AUTOSAR XML (schema 4-3-0)
package /ComponentTypes
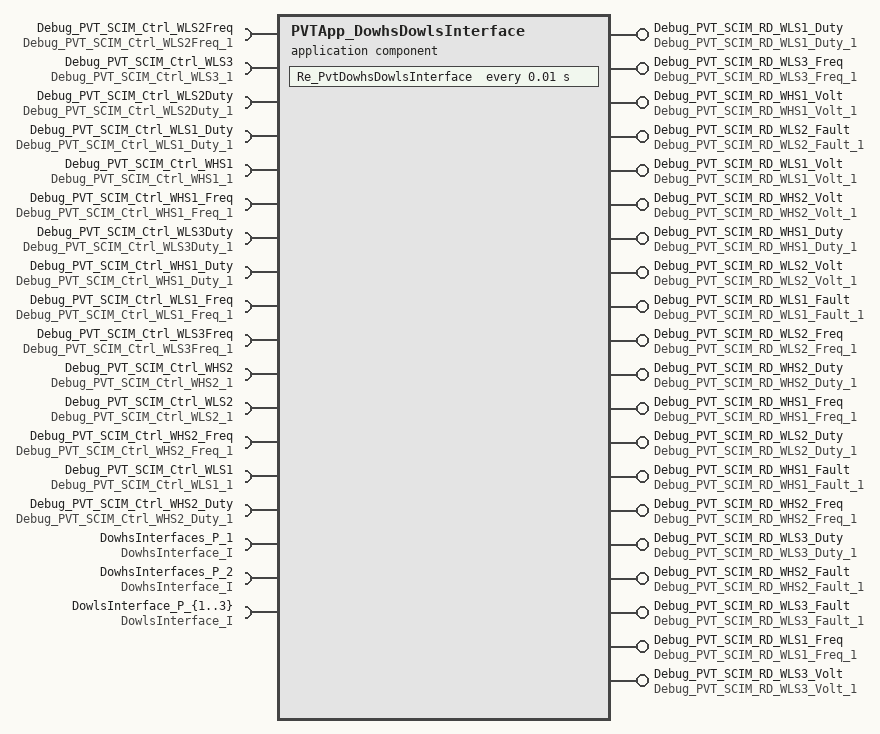
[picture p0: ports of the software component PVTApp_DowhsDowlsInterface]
  application sw component type PVTApp_DowhsDowlsInterface
    15 x require port:
      Debug_PVT_SCIM_Ctrl_WLS2Freq: nonqueued-receiver-com-spec{data-element=Debug_PVT_SCIM_Ctrl_WLS2Freq, init-value=0}, required-interface=Debug_PVT_SCIM_Ctrl_WLS2Freq_1
      Debug_PVT_SCIM_Ctrl_WLS3: nonqueued-receiver-com-spec{data-element=Debug_PVT_SCIM_Ctrl_WLS3, init-value=0}, required-interface=Debug_PVT_SCIM_Ctrl_WLS3_1
      Debug_PVT_SCIM_Ctrl_WLS2Duty: nonqueued-receiver-com-spec{data-element=Debug_PVT_SCIM_Ctrl_WLS2Duty, init-value=0}, required-interface=Debug_PVT_SCIM_Ctrl_WLS2Duty_1
      Debug_PVT_SCIM_Ctrl_WLS1_Duty: nonqueued-receiver-com-spec{data-element=Debug_PVT_SCIM_Ctrl_WLS1_Duty, init-value=0}, required-interface=Debug_PVT_SCIM_Ctrl_WLS1_Duty_1
      Debug_PVT_SCIM_Ctrl_WHS1: nonqueued-receiver-com-spec{data-element=Debug_PVT_SCIM_Ctrl_WHS1, init-value=0}, required-interface=Debug_PVT_SCIM_Ctrl_WHS1_1
      Debug_PVT_SCIM_Ctrl_WHS1_Freq: nonqueued-receiver-com-spec{data-element=Debug_PVT_SCIM_Ctrl_WHS1_Freq, init-value=0}, required-interface=Debug_PVT_SCIM_Ctrl_WHS1_Freq_1
      Debug_PVT_SCIM_Ctrl_WLS3Duty: nonqueued-receiver-com-spec{data-element=Debug_PVT_SCIM_Ctrl_WLS3Duty, init-value=0}, required-interface=Debug_PVT_SCIM_Ctrl_WLS3Duty_1
      Debug_PVT_SCIM_Ctrl_WHS1_Duty: nonqueued-receiver-com-spec{data-element=Debug_PVT_SCIM_Ctrl_WHS1_Duty, init-value=0}, required-interface=Debug_PVT_SCIM_Ctrl_WHS1_Duty_1
      Debug_PVT_SCIM_Ctrl_WLS1_Freq: nonqueued-receiver-com-spec{data-element=Debug_PVT_SCIM_Ctrl_WLS1_Freq, init-value=0}, required-interface=Debug_PVT_SCIM_Ctrl_WLS1_Freq_1
      Debug_PVT_SCIM_Ctrl_WLS3Freq: nonqueued-receiver-com-spec{data-element=Debug_PVT_SCIM_Ctrl_WLS3Freq, init-value=0}, required-interface=Debug_PVT_SCIM_Ctrl_WLS3Freq_1
      Debug_PVT_SCIM_Ctrl_WHS2: nonqueued-receiver-com-spec{data-element=Debug_PVT_SCIM_Ctrl_WHS2, init-value=0}, required-interface=Debug_PVT_SCIM_Ctrl_WHS2_1
      Debug_PVT_SCIM_Ctrl_WLS2: nonqueued-receiver-com-spec{data-element=Debug_PVT_SCIM_Ctrl_WLS2, init-value=0}, required-interface=Debug_PVT_SCIM_Ctrl_WLS2_1
      Debug_PVT_SCIM_Ctrl_WHS2_Freq: nonqueued-receiver-com-spec{data-element=Debug_PVT_SCIM_Ctrl_WHS2_Freq, init-value=0}, required-interface=Debug_PVT_SCIM_Ctrl_WHS2_Freq_1
      Debug_PVT_SCIM_Ctrl_WLS1: nonqueued-receiver-com-spec{data-element=Debug_PVT_SCIM_Ctrl_WLS1, init-value=0}, required-interface=Debug_PVT_SCIM_Ctrl_WLS1_1
      Debug_PVT_SCIM_Ctrl_WHS2_Duty: nonqueued-receiver-com-spec{data-element=Debug_PVT_SCIM_Ctrl_WHS2_Duty, init-value=0}, required-interface=Debug_PVT_SCIM_Ctrl_WHS2_Duty_1
    20 x provide port:
      Debug_PVT_SCIM_RD_WLS1_Duty: nonqueued-sender-com-spec{data-element=Debug_PVT_SCIM_RD_WLS1_Duty, init-value=0}, provided-interface=Debug_PVT_SCIM_RD_WLS1_Duty_1
      Debug_PVT_SCIM_RD_WLS3_Freq: nonqueued-sender-com-spec{data-element=Debug_PVT_SCIM_RD_WLS3_Freq, init-value=0}, provided-interface=Debug_PVT_SCIM_RD_WLS3_Freq_1
      Debug_PVT_SCIM_RD_WHS1_Volt: nonqueued-sender-com-spec{data-element=Debug_PVT_SCIM_RD_WHS1_Volt, init-value=0}, provided-interface=Debug_PVT_SCIM_RD_WHS1_Volt_1
      Debug_PVT_SCIM_RD_WLS2_Fault: nonqueued-sender-com-spec{data-element=Debug_PVT_SCIM_RD_WLS2_Fault, init-value=0}, provided-interface=Debug_PVT_SCIM_RD_WLS2_Fault_1
      Debug_PVT_SCIM_RD_WLS1_Volt: nonqueued-sender-com-spec{data-element=Debug_PVT_SCIM_RD_WLS1_Volt, init-value=0}, provided-interface=Debug_PVT_SCIM_RD_WLS1_Volt_1
      Debug_PVT_SCIM_RD_WHS2_Volt: nonqueued-sender-com-spec{data-element=Debug_PVT_SCIM_RD_WHS2_Volt, init-value=0}, provided-interface=Debug_PVT_SCIM_RD_WHS2_Volt_1
      Debug_PVT_SCIM_RD_WHS1_Duty: nonqueued-sender-com-spec{data-element=Debug_PVT_SCIM_RD_WHS1_Duty, init-value=0}, provided-interface=Debug_PVT_SCIM_RD_WHS1_Duty_1
      Debug_PVT_SCIM_RD_WLS2_Volt: nonqueued-sender-com-spec{data-element=Debug_PVT_SCIM_RD_WLS2_Volt, init-value=0}, provided-interface=Debug_PVT_SCIM_RD_WLS2_Volt_1
      Debug_PVT_SCIM_RD_WLS1_Fault: nonqueued-sender-com-spec{data-element=Debug_PVT_SCIM_RD_WLS1_Fault, init-value=0}, provided-interface=Debug_PVT_SCIM_RD_WLS1_Fault_1
      Debug_PVT_SCIM_RD_WLS2_Freq: nonqueued-sender-com-spec{data-element=Debug_PVT_SCIM_RD_WLS2_Freq, init-value=0}, provided-interface=Debug_PVT_SCIM_RD_WLS2_Freq_1
      Debug_PVT_SCIM_RD_WHS2_Duty: nonqueued-sender-com-spec{data-element=Debug_PVT_SCIM_RD_WHS2_Duty, init-value=0}, provided-interface=Debug_PVT_SCIM_RD_WHS2_Duty_1
      Debug_PVT_SCIM_RD_WHS1_Freq: nonqueued-sender-com-spec{data-element=Debug_PVT_SCIM_RD_WHS1_Freq, init-value=0}, provided-interface=Debug_PVT_SCIM_RD_WHS1_Freq_1
      Debug_PVT_SCIM_RD_WLS2_Duty: nonqueued-sender-com-spec{data-element=Debug_PVT_SCIM_RD_WLS2_Duty, init-value=0}, provided-interface=Debug_PVT_SCIM_RD_WLS2_Duty_1
      Debug_PVT_SCIM_RD_WHS1_Fault: nonqueued-sender-com-spec{data-element=Debug_PVT_SCIM_RD_WHS1_Fault, init-value=0}, provided-interface=Debug_PVT_SCIM_RD_WHS1_Fault_1
      Debug_PVT_SCIM_RD_WHS2_Freq: nonqueued-sender-com-spec{data-element=Debug_PVT_SCIM_RD_WHS2_Freq, init-value=0}, provided-interface=Debug_PVT_SCIM_RD_WHS2_Freq_1
      Debug_PVT_SCIM_RD_WLS3_Duty: nonqueued-sender-com-spec{data-element=Debug_PVT_SCIM_RD_WLS3_Duty, init-value=0}, provided-interface=Debug_PVT_SCIM_RD_WLS3_Duty_1
      Debug_PVT_SCIM_RD_WHS2_Fault: nonqueued-sender-com-spec{data-element=Debug_PVT_SCIM_RD_WHS2_Fault, init-value=0}, provided-interface=Debug_PVT_SCIM_RD_WHS2_Fault_1
      Debug_PVT_SCIM_RD_WLS3_Fault: nonqueued-sender-com-spec{data-element=Debug_PVT_SCIM_RD_WLS3_Fault, init-value=0}, provided-interface=Debug_PVT_SCIM_RD_WLS3_Fault_1
      Debug_PVT_SCIM_RD_WLS1_Freq: nonqueued-sender-com-spec{data-element=Debug_PVT_SCIM_RD_WLS1_Freq, init-value=0}, provided-interface=Debug_PVT_SCIM_RD_WLS1_Freq_1
      Debug_PVT_SCIM_RD_WLS3_Volt: nonqueued-sender-com-spec{data-element=Debug_PVT_SCIM_RD_WLS3_Volt, init-value=0}, provided-interface=Debug_PVT_SCIM_RD_WLS3_Volt_1
    5 x require port:
      DowhsInterfaces_P_1: required-com-specs=[SetDowActive, GetDoPinStateOne], required-interface=DowhsInterface_I
      DowhsInterfaces_P_2: required-com-specs=[SetDowActive, GetDoPinStateOne], required-interface=DowhsInterface_I
      DowlsInterface_P_{1..3}: required-com-specs=[SetDowlsActive, GetDoPinStateOne], required-interface=DowlsInterface_I
    behavior PVTApp_DowhsDowlsInterface_InternalBehavior
      timing event TMT_Re_PvtDowhsDowlsInterface: start-on-event=Re_PvtDowhsDowlsInterface, period=0.01
      runnable Re_PvtDowhsDowlsInterface
        data-receive-point-by-arguments:
          15 x access:
            REC_Debug_PVT_SCIM_Ctrl_WHS1_Debug_PVT_SCIM_Ctrl_WHS1: accessed-variable=Debug_PVT_SCIM_Ctrl_WHS1.Debug_PVT_SCIM_Ctrl_WHS1
            REC_Debug_PVT_SCIM_Ctrl_WHS1_Duty_Debug_PVT_SCIM_Ctrl_WHS1_Duty: accessed-variable=Debug_PVT_SCIM_Ctrl_WHS1_Duty.Debug_PVT_SCIM_Ctrl_WHS1_Duty
            REC_Debug_PVT_SCIM_Ctrl_WHS1_Freq_Debug_PVT_SCIM_Ctrl_WHS1_Freq: accessed-variable=Debug_PVT_SCIM_Ctrl_WHS1_Freq.Debug_PVT_SCIM_Ctrl_WHS1_Freq
            REC_Debug_PVT_SCIM_Ctrl_WHS2_Debug_PVT_SCIM_Ctrl_WHS2: accessed-variable=Debug_PVT_SCIM_Ctrl_WHS2.Debug_PVT_SCIM_Ctrl_WHS2
            REC_Debug_PVT_SCIM_Ctrl_WHS2_Duty_Debug_PVT_SCIM_Ctrl_WHS2_Duty: accessed-variable=Debug_PVT_SCIM_Ctrl_WHS2_Duty.Debug_PVT_SCIM_Ctrl_WHS2_Duty
            REC_Debug_PVT_SCIM_Ctrl_WHS2_Freq_Debug_PVT_SCIM_Ctrl_WHS2_Freq: accessed-variable=Debug_PVT_SCIM_Ctrl_WHS2_Freq.Debug_PVT_SCIM_Ctrl_WHS2_Freq
            REC_Debug_PVT_SCIM_Ctrl_WLS1_Debug_PVT_SCIM_Ctrl_WLS1: accessed-variable=Debug_PVT_SCIM_Ctrl_WLS1.Debug_PVT_SCIM_Ctrl_WLS1
            REC_Debug_PVT_SCIM_Ctrl_WLS1_Duty_Debug_PVT_SCIM_Ctrl_WLS1_Duty: accessed-variable=Debug_PVT_SCIM_Ctrl_WLS1_Duty.Debug_PVT_SCIM_Ctrl_WLS1_Duty
            REC_Debug_PVT_SCIM_Ctrl_WLS1_Freq_Debug_PVT_SCIM_Ctrl_WLS1_Freq: accessed-variable=Debug_PVT_SCIM_Ctrl_WLS1_Freq.Debug_PVT_SCIM_Ctrl_WLS1_Freq
            REC_Debug_PVT_SCIM_Ctrl_WLS2_Debug_PVT_SCIM_Ctrl_WLS2: accessed-variable=Debug_PVT_SCIM_Ctrl_WLS2.Debug_PVT_SCIM_Ctrl_WLS2
            REC_Debug_PVT_SCIM_Ctrl_WLS2Duty_Debug_PVT_SCIM_Ctrl_WLS2Duty: accessed-variable=Debug_PVT_SCIM_Ctrl_WLS2Duty.Debug_PVT_SCIM_Ctrl_WLS2Duty
            REC_Debug_PVT_SCIM_Ctrl_WLS2Freq_Debug_PVT_SCIM_Ctrl_WLS2Freq: accessed-variable=Debug_PVT_SCIM_Ctrl_WLS2Freq.Debug_PVT_SCIM_Ctrl_WLS2Freq
            REC_Debug_PVT_SCIM_Ctrl_WLS3_Debug_PVT_SCIM_Ctrl_WLS3: accessed-variable=Debug_PVT_SCIM_Ctrl_WLS3.Debug_PVT_SCIM_Ctrl_WLS3
            REC_Debug_PVT_SCIM_Ctrl_WLS3Duty_Debug_PVT_SCIM_Ctrl_WLS3Duty: accessed-variable=Debug_PVT_SCIM_Ctrl_WLS3Duty.Debug_PVT_SCIM_Ctrl_WLS3Duty
            REC_Debug_PVT_SCIM_Ctrl_WLS3Freq_Debug_PVT_SCIM_Ctrl_WLS3Freq: accessed-variable=Debug_PVT_SCIM_Ctrl_WLS3Freq.Debug_PVT_SCIM_Ctrl_WLS3Freq
        data-send-points:
          20 x access:
            SEND_Debug_PVT_SCIM_RD_WHS1_Duty_Debug_PVT_SCIM_RD_WHS1_Duty: accessed-variable=Debug_PVT_SCIM_RD_WHS1_Duty.Debug_PVT_SCIM_RD_WHS1_Duty
            SEND_Debug_PVT_SCIM_RD_WHS1_Fault_Debug_PVT_SCIM_RD_WHS1_Fault: accessed-variable=Debug_PVT_SCIM_RD_WHS1_Fault.Debug_PVT_SCIM_RD_WHS1_Fault
            SEND_Debug_PVT_SCIM_RD_WHS1_Freq_Debug_PVT_SCIM_RD_WHS1_Freq: accessed-variable=Debug_PVT_SCIM_RD_WHS1_Freq.Debug_PVT_SCIM_RD_WHS1_Freq
            SEND_Debug_PVT_SCIM_RD_WHS1_Volt_Debug_PVT_SCIM_RD_WHS1_Volt: accessed-variable=Debug_PVT_SCIM_RD_WHS1_Volt.Debug_PVT_SCIM_RD_WHS1_Volt
            SEND_Debug_PVT_SCIM_RD_WHS2_Duty_Debug_PVT_SCIM_RD_WHS2_Duty: accessed-variable=Debug_PVT_SCIM_RD_WHS2_Duty.Debug_PVT_SCIM_RD_WHS2_Duty
            SEND_Debug_PVT_SCIM_RD_WHS2_Fault_Debug_PVT_SCIM_RD_WHS2_Fault: accessed-variable=Debug_PVT_SCIM_RD_WHS2_Fault.Debug_PVT_SCIM_RD_WHS2_Fault
            SEND_Debug_PVT_SCIM_RD_WHS2_Freq_Debug_PVT_SCIM_RD_WHS2_Freq: accessed-variable=Debug_PVT_SCIM_RD_WHS2_Freq.Debug_PVT_SCIM_RD_WHS2_Freq
            SEND_Debug_PVT_SCIM_RD_WHS2_Volt_Debug_PVT_SCIM_RD_WHS2_Volt: accessed-variable=Debug_PVT_SCIM_RD_WHS2_Volt.Debug_PVT_SCIM_RD_WHS2_Volt
            SEND_Debug_PVT_SCIM_RD_WLS1_Duty_Debug_PVT_SCIM_RD_WLS1_Duty: accessed-variable=Debug_PVT_SCIM_RD_WLS1_Duty.Debug_PVT_SCIM_RD_WLS1_Duty
            SEND_Debug_PVT_SCIM_RD_WLS1_Fault_Debug_PVT_SCIM_RD_WLS1_Fault: accessed-variable=Debug_PVT_SCIM_RD_WLS1_Fault.Debug_PVT_SCIM_RD_WLS1_Fault
            SEND_Debug_PVT_SCIM_RD_WLS1_Freq_Debug_PVT_SCIM_RD_WLS1_Freq: accessed-variable=Debug_PVT_SCIM_RD_WLS1_Freq.Debug_PVT_SCIM_RD_WLS1_Freq
            SEND_Debug_PVT_SCIM_RD_WLS1_Volt_Debug_PVT_SCIM_RD_WLS1_Volt: accessed-variable=Debug_PVT_SCIM_RD_WLS1_Volt.Debug_PVT_SCIM_RD_WLS1_Volt
            SEND_Debug_PVT_SCIM_RD_WLS2_Duty_Debug_PVT_SCIM_RD_WLS2_Duty: accessed-variable=Debug_PVT_SCIM_RD_WLS2_Duty.Debug_PVT_SCIM_RD_WLS2_Duty
            SEND_Debug_PVT_SCIM_RD_WLS2_Fault_Debug_PVT_SCIM_RD_WLS2_Fault: accessed-variable=Debug_PVT_SCIM_RD_WLS2_Fault.Debug_PVT_SCIM_RD_WLS2_Fault
            SEND_Debug_PVT_SCIM_RD_WLS2_Freq_Debug_PVT_SCIM_RD_WLS2_Freq: accessed-variable=Debug_PVT_SCIM_RD_WLS2_Freq.Debug_PVT_SCIM_RD_WLS2_Freq
            SEND_Debug_PVT_SCIM_RD_WLS2_Volt_Debug_PVT_SCIM_RD_WLS2_Volt: accessed-variable=Debug_PVT_SCIM_RD_WLS2_Volt.Debug_PVT_SCIM_RD_WLS2_Volt
            SEND_Debug_PVT_SCIM_RD_WLS3_Duty_Debug_PVT_SCIM_RD_WLS3_Duty: accessed-variable=Debug_PVT_SCIM_RD_WLS3_Duty.Debug_PVT_SCIM_RD_WLS3_Duty
            SEND_Debug_PVT_SCIM_RD_WLS3_Fault_Debug_PVT_SCIM_RD_WLS3_Fault: accessed-variable=Debug_PVT_SCIM_RD_WLS3_Fault.Debug_PVT_SCIM_RD_WLS3_Fault
            SEND_Debug_PVT_SCIM_RD_WLS3_Freq_Debug_PVT_SCIM_RD_WLS3_Freq: accessed-variable=Debug_PVT_SCIM_RD_WLS3_Freq.Debug_PVT_SCIM_RD_WLS3_Freq
            SEND_Debug_PVT_SCIM_RD_WLS3_Volt_Debug_PVT_SCIM_RD_WLS3_Volt: accessed-variable=Debug_PVT_SCIM_RD_WLS3_Volt.Debug_PVT_SCIM_RD_WLS3_Volt
        10 x sync call:
          SC_DowhsInterfaces_P_1_GetDoPinStateOne: operation=DowhsInterfaces_P_1.GetDoPinStateOne
          SC_DowhsInterfaces_P_1_SetDowActive: operation=DowhsInterfaces_P_1.SetDowActive
          SC_DowhsInterfaces_P_2_GetDoPinStateOne: operation=DowhsInterfaces_P_2.GetDoPinStateOne
          SC_DowhsInterfaces_P_2_SetDowActive: operation=DowhsInterfaces_P_2.SetDowActive
          SC_DowlsInterface_P_1_GetDoPinStateOne: operation=DowlsInterface_P_1.GetDoPinStateOne
          SC_DowlsInterface_P_1_SetDowlsActive: operation=DowlsInterface_P_1.SetDowlsActive
          SC_DowlsInterface_P_2_GetDoPinStateOne: operation=DowlsInterface_P_2.GetDoPinStateOne
          SC_DowlsInterface_P_2_SetDowlsActive: operation=DowlsInterface_P_2.SetDowlsActive
          SC_DowlsInterface_P_3_GetDoPinStateOne: operation=DowlsInterface_P_3.GetDoPinStateOne
          SC_DowlsInterface_P_3_SetDowlsActive: operation=DowlsInterface_P_3.SetDowlsActive
  swc implementation PVTApp_DowhsDowlsInterface_Implementation: behavior=PVTApp_DowhsDowlsInterface_InternalBehavior
    code-descriptors:
      code Default: artifact-descriptors=autosar-engineering-object=category=SWSRC
